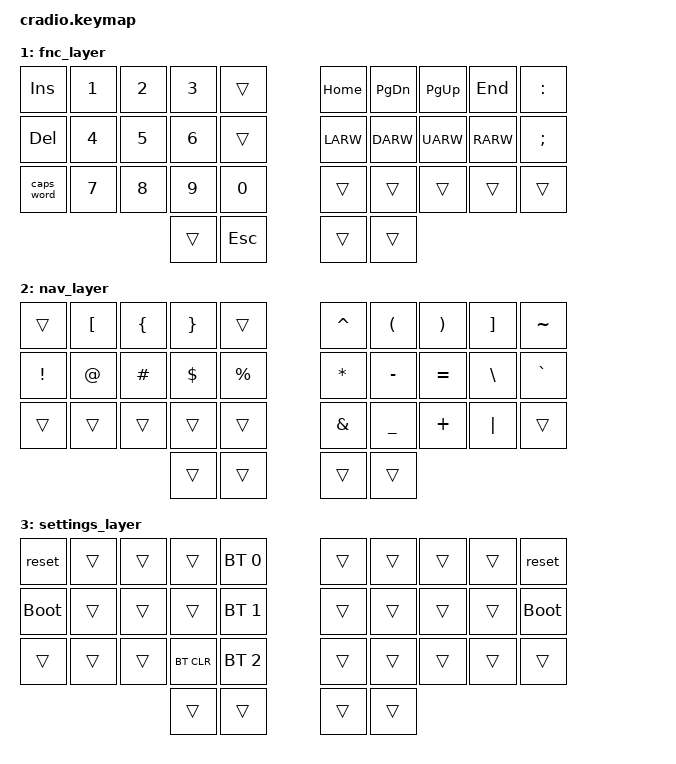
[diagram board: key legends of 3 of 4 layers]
// Copyright (c) 2022 The ZMK Contributors
// SPDX-License-Identifier: MIT

#include <behaviors.dtsi>
#include <dt-bindings/zmk/keys.h>
#include <dt-bindings/zmk/bt.h>

// Layer definitions
    #define BASE 0
    #define FNC 1
    #define NAV 2
    #define GAME 3
    #define SETTINGS 4
// -----------------

// Home row mods macro
#define HRML(k1,k2,k3,k4) &ht LSHFT k1  &ht LALT k2  &ht LCTRL k3  &ht LGUI k4
#define HRMR(k1,k2,k3,k4) &ht RGUI k1  &ht RCTRL k2  &ht RALT k3  &ht RSHFT k4

/ {
    behaviors {
        ht: hold_tap {
            label = "hold_tap";
            compatible = "zmk,behavior-hold-tap";
            #binding-cells = <2>;
            flavor = "tap-preferred";
            tapping-term-ms = <220>;
            quick-tap-ms = <150>;
            global-quick-tap;
            bindings = <&kp>, <&kp>;
        };
    };
    
    combos {
        compatible = "zmk,combos";
        
				// LR Thumb Key & RR Thumb Key 
				combo_nav {
						timeout-ms = <200>;
						key-positions = <31 33>;
						bindings = <&kt NAV>;
				};
				// LR Thumb Key & RL Thumb Key 
				combo_fnc {
						timeout-ms = <200>;
						key-positions = <31 33>;
						bindings = <&sl FNC>;
				};
				// RR Thumb Key & RR Thumb Key 
				combo_game {
						timeout-ms = <200>;
						key-positions = <30 33>;
						bindings = <&kt GAME>;
				};
				// both left thumb keys
				combo_settings {
						timeout-ms = <300>;
						key-positions = <30 31>;
						bindings = <&mo SETTINGS>;
				};
    };

    keymap {
        compatible = "zmk,keymap";
	default_layer {
    		bindings = <
        //╭──────────┬──────────┬──────────┬──────────┬──────────╮   ╭──────────┬──────────┬──────────┬──────────┬──────────╮
        //│  J       │  C       │  Y       │  F       │  K       │   │  Z       │  L       │  , <     │  U       │  Q       │
            &ht ESC J   &kp C      &kp Y      &kp F      &kp K          &kp Z      &kp L      &kp COMMA  &kp U      &kp Q
        //├──────────┼──────────┼──────────┼──────────┼──────────┤   ├──────────┼──────────┼──────────┼──────────┼──────────┤
        //│  R       │  S       │  T       │  H       │  D       │   │  M       │  N       │  A       │  I       │   O      │
            HRML(R,        S,         T,         H)     &kp D          &kp M      HRMR(N,        A,         I,          O)
        //├──────────┼──────────┼──────────┼──────────┼──────────┤   ├──────────┼──────────┼──────────┼──────────┼──────────┤
        //│ / ?      │  V       │  G       │  P       │  B       │   │  X       │  W       │ . >      │ ; :      │ - _      │
            &kp FSLH     &kp V      &kp G      &kp P      &kp B          &kp X      &kp W      &kp DOT  &kp SEMI   &kp MINUS
        //╰──────────┴──────────┼──────────┼──────────┴──────────┤   ├──────────┼──────────┼──────────┴──────────┴──────────╯
                                               &kp E    &kp ENTER  &ht INS SPACE &ht DEL BSPC
        //                                 ╰──────────┴──────────╯   ╰──────────┴──────────╯
		>;
	};

        fnc_layer {
		bindings = <
        //╭──────────┬──────────┬──────────┬──────────┬──────────╮   ╭──────────┬──────────┬──────────┬──────────┬──────────╮
        //│ INSERT   │  1       │  2       │  3       │          │   │ HOME     │ PAGE DN  │ PAGE UP  │ END      │  :       │
            &kp INS    &kp N1     &kp N2     &kp N3     &trans         &kp HOME   &kp PG_DN  &kp PG_UP  &kp END    &kp COLON
        //├──────────┼──────────┼──────────┼──────────┼──────────┤   ├──────────┼──────────┼──────────┼──────────┼──────────┤
        //│ DELETE   │  4       │  5       │  6       │          │   │ LEFT     │ DOWN     │ UP       │ RIGHT    │  ;       │
            &kp DEL    &kp N4     &kp N5     &kp N6     &trans         &kp LARW   &kp DARW   &kp UARW   &kp RARW   &kp SEMI
        //├──────────┼──────────┼──────────┼──────────┼──────────┤   ├──────────┼──────────┼──────────┼──────────┼──────────┤
        //│ CAPS     │  7       │  8       │  9       │  0       │   │          │          │          │          │          │
           &caps_word  &kp N7     &kp N8     &kp N9     &kp N0         &trans     &trans     &trans     &trans     &trans
        //╰──────────┴──────────┴──────────┼──────────┼──────────┤   ├──────────┼──────────┼──────────┴──────────┴──────────╯
                                             &trans     &kp ESC        &trans     &trans
        //                                 ╰──────────┴──────────╯   ╰──────────┴──────────╯
            >;
        };

        nav_layer {
            bindings = <
        //╭──────────┬──────────┬──────────┬──────────┬──────────╮   ╭──────────┬──────────┬──────────┬──────────┬──────────╮
        //│          │  [       │  {       │  }       │          │   │  ^       │  (       │  )       │  ]       │  ~       │
            &trans     &kp LBKT   &kp LBRC   &kp RBRC   &trans         &kp CARET  &kp LPAR   &kp RPAR   &kp RBKT   &kp TILDE
        //├──────────┼──────────┼──────────┼──────────┼──────────┤   ├──────────┼──────────┼──────────┼──────────┼──────────┤
        //│  !       │  @       │  #       │  $       │  %       │   │  *       │  -       │  =       │  \       │  `       │
            &kp EXCL   &kp AT     &kp HASH   &kp DLLR   &kp PRCNT      &kp ASTRK  &kp MINUS  &kp EQUAL  &kp BSLH   &kp GRAVE
        //├──────────┼──────────┼──────────┼──────────┼──────────┤   ├──────────┼──────────┼──────────┼──────────┼──────────┤
        //│          │          │          │          │          │   │  &       │  _       │  +       │  │       │          │
            &trans     &trans     &trans     &trans     &trans         &kp AMPS   &kp UNDER  &kp PLUS   &kp PIPE   &trans
        //╰──────────┴──────────┴──────────┼──────────┼──────────┤   ├──────────┼──────────┼──────────┴──────────┴──────────╯
                                             &trans     &trans         &trans     &trans
        //                                 ╰──────────┴──────────╯   ╰──────────┴──────────╯
            >;
        };

        settings_layer {
            bindings = <
        //╭──────────┬──────────┬──────────┬──────────┬──────────╮   ╭──────────┬──────────┬──────────┬──────────┬──────────╮
        //│ RESET    │          │          │          │PROFILE 0 │   │          │          │          │          │  RESET   │
            &reset     &trans     &trans     &trans    &bt BT_SEL 0    &trans     &trans     &trans     &trans      &reset
        //├──────────┼──────────┼──────────┼──────────┼──────────┤   ├──────────┼──────────┼──────────┼──────────┼──────────┤
        //│BOOTLOADER│          │          │          │PROFILE 1 │   │          │          │          │          │BOOTLOADER│
          &bootloader  &trans     &trans     &trans    &bt BT_SEL 1    &trans     &trans     &trans     &trans    &bootloader
        //├──────────┼──────────┼──────────┼──────────┼──────────┤   ├──────────┼──────────┼──────────┼──────────┼──────────┤
        //│          │          │          │ CLEAR BT │PROFILE 2 │   │          │          │          │          │          │
            &trans     &trans     &trans    &bt BT_CLR &bt BT_SEL 2    &trans     &trans     &trans     &trans     &trans
        //╰──────────┴──────────┴──────────┼──────────┼──────────┤   ├──────────┼──────────┼──────────┴──────────┴──────────╯
                                             &trans     &trans         &trans     &trans
        //                                 ╰──────────┴──────────╯   ╰──────────┴──────────╯
            >;
        };
    };
};

